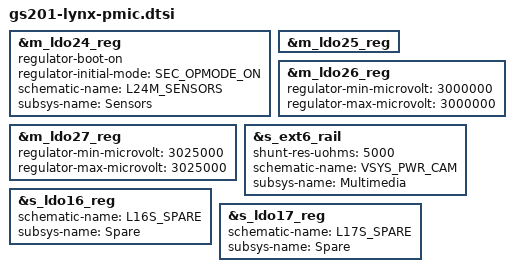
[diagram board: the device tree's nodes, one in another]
// SPDX-License-Identifier: GPL-2.0-only
/*
 * Lynx-specific PMIC settings
 *
 * Copyright 2021 Google LLC.
 *
 */

/* Mag sensor: 1v8 power source. */
&m_ldo24_reg {
	regulator-boot-on;
	regulator-initial-mode = <SEC_OPMODE_ON>;
	schematic-name = "L24M_SENSORS";
	subsys-name = "Sensors";
};

/* Touch: touch controller requires 3.0v typ */
&m_ldo25_reg {
	/delete-property/ regulator-always-on;
};

&m_ldo26_reg {
	regulator-min-microvolt = <3000000>;
	regulator-max-microvolt = <3000000>;
	/delete-property/ regulator-always-on;
};

/* Display: vci-supply voltage */
&m_ldo27_reg {
	regulator-min-microvolt = <3025000>;
	regulator-max-microvolt = <3025000>;
};

&s_ext6_rail {
	shunt-res-uohms = <5000>;
	schematic-name = "VSYS_PWR_CAM";
	subsys-name = "Multimedia";
};

&s_ldo16_reg {
	schematic-name = "L16S_SPARE";
	subsys-name = "Spare";
};

&s_ldo17_reg {
	schematic-name = "L17S_SPARE";
	subsys-name = "Spare";
};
